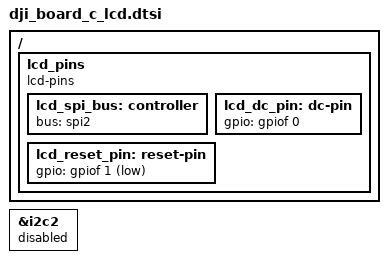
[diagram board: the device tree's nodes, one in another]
/ {
	lcd_pins {
		compatible = "lcd-pins";

		lcd_spi_bus: controller {
			status = "okay";
			bus = <&spi2>;
		};

		lcd_dc_pin: dc-pin {
			status = "okay";
			gpio = <&gpiof 0 GPIO_ACTIVE_HIGH>;
		};

		lcd_reset_pin: reset-pin {
			status = "okay";
			gpio = <&gpiof 1 GPIO_ACTIVE_LOW>;
		};
	};
};

&i2c2 {
	status = "disabled";
};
